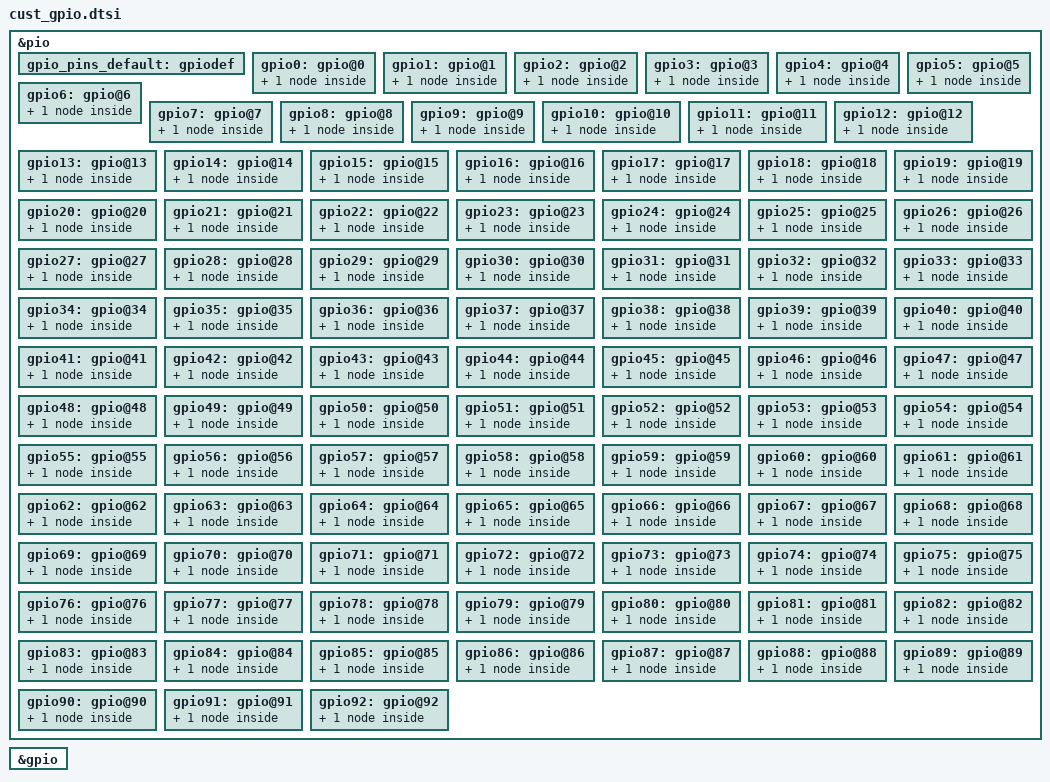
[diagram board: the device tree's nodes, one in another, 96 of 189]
/*
 * Generated by MTK SP DrvGen Version 03.13.6 for MT6580. Copyright MediaTek Inc. (C) 2013.
 * Sat Sep 10 16:33:29 2016
 * Do Not Modify the File.
 */

/*************************
 * GPIO DTSI File
*************************/

&pio {

	gpio_pins_default: gpiodef{
	};

	gpio0: gpio@0 {
		pins_cmd_dat {
			pins = <PINMUX_GPIO0__FUNC_SPI1_CS>;
			slew-rate = <0>;
			
			bias-pull-down = <00>;
			output-low;
			input-schmitt-enable = <0>;
		};
	};

	gpio1: gpio@1 {
		pins_cmd_dat {
			pins = <PINMUX_GPIO1__FUNC_SPI1_SCK>;
			slew-rate = <1>;
			
			bias-pull-down = <00>;
			output-low;
			input-schmitt-enable = <0>;
		};
	};

	gpio2: gpio@2 {
		pins_cmd_dat {
			pins = <PINMUX_GPIO2__FUNC_SPI1_MOSI>;
			slew-rate = <1>;
			bias-disable;
			bias-pull-down = <00>;
			output-low;
			input-schmitt-enable = <0>;
		};
	};

	gpio3: gpio@3 {
		pins_cmd_dat {
			pins = <PINMUX_GPIO3__FUNC_SPI1_MISO>;
			slew-rate = <0>;
			
			bias-pull-down = <11>;
			output-low;
			input-schmitt-enable = <0>;
		};
	};

	gpio4: gpio@4 {
		pins_cmd_dat {
			pins = <PINMUX_GPIO4__FUNC_GPIO4>;
			slew-rate = <1>;
			bias-disable;
			bias-pull-down = <00>;
			output-high;
			input-schmitt-enable = <0>;
		};
	};

	gpio5: gpio@5 {
		pins_cmd_dat {
			pins = <PINMUX_GPIO5__FUNC_EINT5>;
			slew-rate = <0>;
			
			bias-pull-down = <00>;
			output-low;
			input-schmitt-enable = <1>;
		};
	};

	gpio6: gpio@6 {
		pins_cmd_dat {
			pins = <PINMUX_GPIO6__FUNC_EINT6>;
			slew-rate = <0>;
			
			bias-pull-down = <11>;
			output-high;
			input-schmitt-enable = <0>;
		};
	};

	gpio7: gpio@7 {
		pins_cmd_dat {
			pins = <PINMUX_GPIO7__FUNC_GPIO7>;
			slew-rate = <1>;
			bias-disable;
			bias-pull-down = <00>;
			output-low;
			input-schmitt-enable = <0>;
		};
	};

	gpio8: gpio@8 {
		pins_cmd_dat {
			pins = <PINMUX_GPIO8__FUNC_GPIO8>;
			slew-rate = <1>;
			bias-disable;
			bias-pull-down = <00>;
			output-low;
			input-schmitt-enable = <0>;
		};
	};

	gpio9: gpio@9 {
		pins_cmd_dat {
			pins = <PINMUX_GPIO9__FUNC_GPIO9>;
			slew-rate = <0>;
			
			bias-pull-down = <00>;
			output-low;
			input-schmitt-enable = <0>;
		};
	};

	gpio10: gpio@10 {
		pins_cmd_dat {
			pins = <PINMUX_GPIO10__FUNC_GPIO10>;
			slew-rate = <0>;
			
			bias-pull-down = <00>;
			output-low;
			input-schmitt-enable = <0>;
		};
	};

	gpio11: gpio@11 {
		pins_cmd_dat {
			pins = <PINMUX_GPIO11__FUNC_EINT11>;
			slew-rate = <1>;
			bias-disable;
			bias-pull-down = <00>;
			output-low;
			input-schmitt-enable = <0>;
		};
	};

	gpio12: gpio@12 {
		pins_cmd_dat {
			pins = <PINMUX_GPIO12__FUNC_GPIO12>;
			slew-rate = <1>;
			bias-disable;
			bias-pull-down = <00>;
			output-low;
			input-schmitt-enable = <0>;
		};
	};

	gpio13: gpio@13 {
		pins_cmd_dat {
			pins = <PINMUX_GPIO13__FUNC_PMIC_EINT>;
			slew-rate = <0>;
			bias-disable;
			bias-pull-down = <00>;
			output-low;
			input-schmitt-enable = <0>;
		};
	};

	gpio14: gpio@14 {
		pins_cmd_dat {
			pins = <PINMUX_GPIO14__FUNC_EINT14>;
			slew-rate = <1>;
			
			bias-pull-down = <11>;
			output-low;
			input-schmitt-enable = <0>;
		};
	};

	gpio15: gpio@15 {
		pins_cmd_dat {
			pins = <PINMUX_GPIO15__FUNC_GPIO15>;
			slew-rate = <1>;
			
			bias-pull-down = <11>;
			output-low;
			input-schmitt-enable = <0>;
		};
	};

	gpio16: gpio@16 {
		pins_cmd_dat {
			pins = <PINMUX_GPIO16__FUNC_EINT0>;
			slew-rate = <1>;
			bias-disable;
			bias-pull-down = <00>;
			output-low;
			input-schmitt-enable = <0>;
		};
	};

	gpio17: gpio@17 {
		pins_cmd_dat {
			pins = <PINMUX_GPIO17__FUNC_GPIO17>;
			slew-rate = <1>;
			bias-disable;
			bias-pull-down = <00>;
			output-low;
			input-schmitt-enable = <0>;
		};
	};

	gpio18: gpio@18 {
		pins_cmd_dat {
			pins = <PINMUX_GPIO18__FUNC_GPIO18>;
			slew-rate = <1>;
			bias-disable;
			bias-pull-down = <00>;
			output-low;
			input-schmitt-enable = <0>;
		};
	};

	gpio19: gpio@19 {
		pins_cmd_dat {
			pins = <PINMUX_GPIO19__FUNC_GPIO19>;
			slew-rate = <0>;
			
			bias-pull-down = <00>;
			output-low;
			input-schmitt-enable = <0>;
		};
	};

	gpio20: gpio@20 {
		pins_cmd_dat {
			pins = <PINMUX_GPIO20__FUNC_GPIO20>;
			slew-rate = <1>;
			bias-disable;
			bias-pull-down = <00>;
			output-low;
			input-schmitt-enable = <0>;
		};
	};

	gpio21: gpio@21 {
		pins_cmd_dat {
			pins = <PINMUX_GPIO21__FUNC_GPIO21>;
			slew-rate = <1>;
			
			bias-pull-down = <11>;
			output-low;
			input-schmitt-enable = <0>;
		};
	};

	gpio22: gpio@22 {
		pins_cmd_dat {
			pins = <PINMUX_GPIO22__FUNC_SIM1_SCLK>;
			slew-rate = <1>;
			bias-disable;
			bias-pull-down = <00>;
			output-low;
			input-schmitt-enable = <0>;
		};
	};

	gpio23: gpio@23 {
		pins_cmd_dat {
			pins = <PINMUX_GPIO23__FUNC_SIM1_SIO>;
			slew-rate = <1>;
			bias-disable;
			bias-pull-down = <00>;
			output-low;
			input-schmitt-enable = <0>;
		};
	};

	gpio24: gpio@24 {
		pins_cmd_dat {
			pins = <PINMUX_GPIO24__FUNC_SIM2_SIO>;
			slew-rate = <1>;
			bias-disable;
			bias-pull-down = <00>;
			output-low;
			input-schmitt-enable = <0>;
		};
	};

	gpio25: gpio@25 {
		pins_cmd_dat {
			pins = <PINMUX_GPIO25__FUNC_SIM2_SCLK>;
			slew-rate = <1>;
			bias-disable;
			bias-pull-down = <00>;
			output-low;
			input-schmitt-enable = <0>;
		};
	};

	gpio26: gpio@26 {
		pins_cmd_dat {
			pins = <PINMUX_GPIO26__FUNC_AUD_CLK_MOSI>;
			slew-rate = <1>;
			bias-disable;
			bias-pull-down = <00>;
			output-low;
			input-schmitt-enable = <0>;
		};
	};

	gpio27: gpio@27 {
		pins_cmd_dat {
			pins = <PINMUX_GPIO27__FUNC_AUD_DAT_MOSI>;
			slew-rate = <1>;
			bias-disable;
			bias-pull-down = <00>;
			output-low;
			input-schmitt-enable = <0>;
		};
	};

	gpio28: gpio@28 {
		pins_cmd_dat {
			pins = <PINMUX_GPIO28__FUNC_AUD_DAT_MISO>;
			slew-rate = <0>;
			bias-disable;
			bias-pull-down = <00>;
			output-low;
			input-schmitt-enable = <0>;
		};
	};

	gpio29: gpio@29 {
		pins_cmd_dat {
			pins = <PINMUX_GPIO29__FUNC_PMIC_SPI_CSN>;
			slew-rate = <1>;
			bias-disable;
			bias-pull-down = <00>;
			output-low;
			input-schmitt-enable = <1>;
		};
	};

	gpio30: gpio@30 {
		pins_cmd_dat {
			pins = <PINMUX_GPIO30__FUNC_PMIC_SPI_SCK>;
			slew-rate = <1>;
			bias-disable;
			bias-pull-down = <00>;
			output-low;
			input-schmitt-enable = <1>;
		};
	};

	gpio31: gpio@31 {
		pins_cmd_dat {
			pins = <PINMUX_GPIO31__FUNC_PMIC_SPI_MOSI>;
			slew-rate = <1>;
			bias-disable;
			bias-pull-down = <00>;
			output-low;
			input-schmitt-enable = <1>;
		};
	};

	gpio32: gpio@32 {
		pins_cmd_dat {
			pins = <PINMUX_GPIO32__FUNC_PMIC_SPI_MISO>;
			slew-rate = <0>;
			bias-disable;
			bias-pull-down = <00>;
			output-low;
			input-schmitt-enable = <1>;
		};
	};

	gpio33: gpio@33 {
		pins_cmd_dat {
			pins = <PINMUX_GPIO33__FUNC_WATCHDOG>;
			slew-rate = <1>;
			bias-disable;
			bias-pull-down = <00>;
			output-low;
			input-schmitt-enable = <0>;
		};
	};

	gpio34: gpio@34 {
		pins_cmd_dat {
			pins = <PINMUX_GPIO34__FUNC_GPIO34>;
			slew-rate = <1>;
			bias-disable;
			bias-pull-down = <00>;
			output-low;
			input-schmitt-enable = <0>;
		};
	};

	gpio35: gpio@35 {
		pins_cmd_dat {
			pins = <PINMUX_GPIO35__FUNC_PAD_RDP0_A>;
			slew-rate = <0>;
			
			bias-pull-down = <00>;
			output-low;
			input-schmitt-enable = <0>;
		};
	};

	gpio36: gpio@36 {
		pins_cmd_dat {
			pins = <PINMUX_GPIO36__FUNC_PAD_RDN0_A>;
			slew-rate = <0>;
			
			bias-pull-down = <00>;
			output-low;
			input-schmitt-enable = <0>;
		};
	};

	gpio37: gpio@37 {
		pins_cmd_dat {
			pins = <PINMUX_GPIO37__FUNC_PAD_RDP1_A>;
			slew-rate = <0>;
			
			bias-pull-down = <00>;
			output-low;
			input-schmitt-enable = <0>;
		};
	};

	gpio38: gpio@38 {
		pins_cmd_dat {
			pins = <PINMUX_GPIO38__FUNC_PAD_RDN1_A>;
			slew-rate = <0>;
			
			bias-pull-down = <00>;
			output-low;
			input-schmitt-enable = <0>;
		};
	};

	gpio39: gpio@39 {
		pins_cmd_dat {
			pins = <PINMUX_GPIO39__FUNC_PAD_RCP_A>;
			slew-rate = <0>;
			
			bias-pull-down = <00>;
			output-low;
			input-schmitt-enable = <0>;
		};
	};

	gpio40: gpio@40 {
		pins_cmd_dat {
			pins = <PINMUX_GPIO40__FUNC_PAD_RCN_A>;
			slew-rate = <0>;
			
			bias-pull-down = <00>;
			output-low;
			input-schmitt-enable = <0>;
		};
	};

	gpio41: gpio@41 {
		pins_cmd_dat {
			pins = <PINMUX_GPIO41__FUNC_MC0_CK>;
			slew-rate = <1>;
			bias-disable;
			bias-pull-down = <00>;
			output-low;
			input-schmitt-enable = <0>;
		};
	};

	gpio42: gpio@42 {
		pins_cmd_dat {
			pins = <PINMUX_GPIO42__FUNC_MC0_CMD>;
			slew-rate = <0>;
			
			bias-pull-down = <11>;
			output-low;
			input-schmitt-enable = <0>;
		};
	};

	gpio43: gpio@43 {
		pins_cmd_dat {
			pins = <PINMUX_GPIO43__FUNC_MC0_DAT0>;
			slew-rate = <0>;
			
			bias-pull-down = <11>;
			output-low;
			input-schmitt-enable = <0>;
		};
	};

	gpio44: gpio@44 {
		pins_cmd_dat {
			pins = <PINMUX_GPIO44__FUNC_MC0_DAT1>;
			slew-rate = <0>;
			
			bias-pull-down = <11>;
			output-low;
			input-schmitt-enable = <0>;
		};
	};

	gpio45: gpio@45 {
		pins_cmd_dat {
			pins = <PINMUX_GPIO45__FUNC_MC0_DAT2>;
			slew-rate = <0>;
			
			bias-pull-down = <11>;
			output-low;
			input-schmitt-enable = <0>;
		};
	};

	gpio46: gpio@46 {
		pins_cmd_dat {
			pins = <PINMUX_GPIO46__FUNC_MC0_DAT3>;
			slew-rate = <0>;
			
			bias-pull-down = <11>;
			output-low;
			input-schmitt-enable = <0>;
		};
	};

	gpio47: gpio@47 {
		pins_cmd_dat {
			pins = <PINMUX_GPIO47__FUNC_MC0_DAT4>;
			slew-rate = <0>;
			
			bias-pull-down = <11>;
			output-low;
			input-schmitt-enable = <0>;
		};
	};

	gpio48: gpio@48 {
		pins_cmd_dat {
			pins = <PINMUX_GPIO48__FUNC_MC0_DAT5>;
			slew-rate = <0>;
			
			bias-pull-down = <11>;
			output-low;
			input-schmitt-enable = <0>;
		};
	};

	gpio49: gpio@49 {
		pins_cmd_dat {
			pins = <PINMUX_GPIO49__FUNC_MC0_DAT6>;
			slew-rate = <0>;
			
			bias-pull-down = <11>;
			output-low;
			input-schmitt-enable = <0>;
		};
	};

	gpio50: gpio@50 {
		pins_cmd_dat {
			pins = <PINMUX_GPIO50__FUNC_MC0_DAT7>;
			slew-rate = <0>;
			
			bias-pull-down = <11>;
			output-low;
			input-schmitt-enable = <0>;
		};
	};

	gpio51: gpio@51 {
		pins_cmd_dat {
			pins = <PINMUX_GPIO51__FUNC_MC0_RSTB>;
			slew-rate = <1>;
			bias-disable;
			bias-pull-down = <00>;
			output-high;
			input-schmitt-enable = <0>;
		};
	};

	gpio52: gpio@52 {
		pins_cmd_dat {
			pins = <PINMUX_GPIO52__FUNC_MSDC1_CLK>;
			slew-rate = <1>;
			bias-disable;
			bias-pull-down = <00>;
			output-low;
			input-schmitt-enable = <0>;
		};
	};

	gpio53: gpio@53 {
		pins_cmd_dat {
			pins = <PINMUX_GPIO53__FUNC_MSDC1_CMD>;
			slew-rate = <0>;
			
			bias-pull-down = <11>;
			output-low;
			input-schmitt-enable = <0>;
		};
	};

	gpio54: gpio@54 {
		pins_cmd_dat {
			pins = <PINMUX_GPIO54__FUNC_MSDC1_DAT3>;
			slew-rate = <0>;
			
			bias-pull-down = <11>;
			output-low;
			input-schmitt-enable = <0>;
		};
	};

	gpio55: gpio@55 {
		pins_cmd_dat {
			pins = <PINMUX_GPIO55__FUNC_MSDC1_DAT2>;
			slew-rate = <0>;
			
			bias-pull-down = <11>;
			output-low;
			input-schmitt-enable = <0>;
		};
	};

	gpio56: gpio@56 {
		pins_cmd_dat {
			pins = <PINMUX_GPIO56__FUNC_MSDC1_DAT1>;
			slew-rate = <0>;
			
			bias-pull-down = <11>;
			output-low;
			input-schmitt-enable = <0>;
		};
	};

	gpio57: gpio@57 {
		pins_cmd_dat {
			pins = <PINMUX_GPIO57__FUNC_MSDC1_DAT0>;
			slew-rate = <0>;
			
			bias-pull-down = <11>;
			output-low;
			input-schmitt-enable = <0>;
		};
	};

	gpio58: gpio@58 {
		pins_cmd_dat {
			pins = <PINMUX_GPIO58__FUNC_I2C_SCL0>;
			slew-rate = <0>;
			bias-disable;
			bias-pull-down = <00>;
			output-low;
			input-schmitt-enable = <0>;
		};
	};

	gpio59: gpio@59 {
		pins_cmd_dat {
			pins = <PINMUX_GPIO59__FUNC_I2C_SCL1>;
			slew-rate = <0>;
			bias-disable;
			bias-pull-down = <00>;
			output-low;
			input-schmitt-enable = <0>;
		};
	};

	gpio60: gpio@60 {
		pins_cmd_dat {
			pins = <PINMUX_GPIO60__FUNC_I2C_SCL2>;
			slew-rate = <0>;
			bias-disable;
			bias-pull-down = <00>;
			output-low;
			input-schmitt-enable = <0>;
		};
	};

	gpio61: gpio@61 {
		pins_cmd_dat {
			pins = <PINMUX_GPIO61__FUNC_I2C_SDA0>;
			slew-rate = <0>;
			bias-disable;
			bias-pull-down = <00>;
			output-low;
			input-schmitt-enable = <0>;
		};
	};

	gpio62: gpio@62 {
		pins_cmd_dat {
			pins = <PINMUX_GPIO62__FUNC_I2C_SDA1>;
			slew-rate = <0>;
			bias-disable;
			bias-pull-down = <00>;
			output-low;
			input-schmitt-enable = <0>;
		};
	};

	gpio63: gpio@63 {
		pins_cmd_dat {
			pins = <PINMUX_GPIO63__FUNC_I2C_SDA2>;
			slew-rate = <0>;
			bias-disable;
			bias-pull-down = <00>;
			output-low;
			input-schmitt-enable = <0>;
		};
	};

	gpio64: gpio@64 {
		pins_cmd_dat {
			pins = <PINMUX_GPIO64__FUNC_KPCOL0>;
			slew-rate = <0>;
			
			bias-pull-down = <11>;
			output-low;
			input-schmitt-enable = <0>;
		};
	};

	gpio65: gpio@65 {
		pins_cmd_dat {
			pins = <PINMUX_GPIO65__FUNC_KPROW1>;
			slew-rate = <1>;
			bias-disable;
			bias-pull-down = <00>;
			output-low;
			input-schmitt-enable = <0>;
		};
	};

	gpio66: gpio@66 {
		pins_cmd_dat {
			pins = <PINMUX_GPIO66__FUNC_DISP_PWM>;
			slew-rate = <1>;
			bias-disable;
			bias-pull-down = <00>;
			output-low;
			input-schmitt-enable = <0>;
		};
	};

	gpio67: gpio@67 {
		pins_cmd_dat {
			pins = <PINMUX_GPIO67__FUNC_KPCOL1>;
			slew-rate = <0>;
			
			bias-pull-down = <11>;
			output-low;
			input-schmitt-enable = <0>;
		};
	};

	gpio68: gpio@68 {
		pins_cmd_dat {
			pins = <PINMUX_GPIO68__FUNC_DSI_TE>;
			slew-rate = <0>;
			bias-disable;
			bias-pull-down = <00>;
			output-low;
			input-schmitt-enable = <0>;
		};
	};

	gpio69: gpio@69 {
		pins_cmd_dat {
			pins = <PINMUX_GPIO69__FUNC_KPROW0>;
			slew-rate = <1>;
			bias-disable;
			bias-pull-down = <00>;
			output-low;
			input-schmitt-enable = <0>;
		};
	};

	gpio70: gpio@70 {
		pins_cmd_dat {
			pins = <PINMUX_GPIO70__FUNC_LCM_RST>;
			slew-rate = <1>;
			bias-disable;
			bias-pull-down = <00>;
			output-low;
			input-schmitt-enable = <0>;
		};
	};

	gpio71: gpio@71 {
		pins_cmd_dat {
			pins = <PINMUX_GPIO71__FUNC_GPIO71>;
			slew-rate = <1>;
			bias-disable;
			bias-pull-down = <00>;
			output-low;
			input-schmitt-enable = <0>;
		};
	};

	gpio72: gpio@72 {
		pins_cmd_dat {
			pins = <PINMUX_GPIO72__FUNC_CAM_CLK0>;
			slew-rate = <1>;
			bias-disable;
			bias-pull-down = <00>;
			output-low;
			input-schmitt-enable = <0>;
		};
	};

	gpio73: gpio@73 {
		pins_cmd_dat {
			pins = <PINMUX_GPIO73__FUNC_GPIO73>;
			slew-rate = <1>;
			bias-disable;
			bias-pull-down = <00>;
			output-low;
			input-schmitt-enable = <0>;
		};
	};

	gpio74: gpio@74 {
		pins_cmd_dat {
			pins = <PINMUX_GPIO74__FUNC_GPIO74>;
			slew-rate = <1>;
			bias-disable;
			bias-pull-down = <00>;
			output-low;
			input-schmitt-enable = <0>;
		};
	};

	gpio75: gpio@75 {
		pins_cmd_dat {
			pins = <PINMUX_GPIO75__FUNC_CAM_CLK1>;
			slew-rate = <1>;
			bias-disable;
			bias-pull-down = <00>;
			output-low;
			input-schmitt-enable = <0>;
		};
	};

	gpio76: gpio@76 {
		pins_cmd_dat {
			pins = <PINMUX_GPIO76__FUNC_GPIO76>;
			slew-rate = <1>;
			bias-disable;
			bias-pull-down = <00>;
			output-low;
			input-schmitt-enable = <0>;
		};
	};

	gpio77: gpio@77 {
		pins_cmd_dat {
			pins = <PINMUX_GPIO77__FUNC_MD_EINT1>;
			slew-rate = <0>;
			
			bias-pull-down = <11>;
			output-high;
			input-schmitt-enable = <0>;
		};
	};

	gpio78: gpio@78 {
		pins_cmd_dat {
			pins = <PINMUX_GPIO78__FUNC_MD_EINT2>;
			slew-rate = <0>;
			
			bias-pull-down = <11>;
			output-high;
			input-schmitt-enable = <0>;
		};
	};

	gpio79: gpio@79 {
		pins_cmd_dat {
			pins = <PINMUX_GPIO79__FUNC_VM1>;
			slew-rate = <0>;
			bias-disable;
			bias-pull-down = <00>;
			output-low;
			input-schmitt-enable = <0>;
		};
	};

	gpio80: gpio@80 {
		pins_cmd_dat {
			pins = <PINMUX_GPIO80__FUNC_VM0>;
			slew-rate = <0>;
			bias-disable;
			bias-pull-down = <00>;
			output-low;
			input-schmitt-enable = <0>;
		};
	};

	gpio81: gpio@81 {
		pins_cmd_dat {
			pins = <PINMUX_GPIO81__FUNC_BPI_BUS11>;
			slew-rate = <1>;
			bias-disable;
			bias-pull-down = <11>;
			output-low;
			input-schmitt-enable = <0>;
		};
	};

	gpio82: gpio@82 {
		pins_cmd_dat {
			pins = <PINMUX_GPIO82__FUNC_BPI_BUS10>;
			slew-rate = <1>;
			bias-disable;
			bias-pull-down = <00>;
			output-low;
			input-schmitt-enable = <0>;
		};
	};

	gpio83: gpio@83 {
		pins_cmd_dat {
			pins = <PINMUX_GPIO83__FUNC_EINT2>;
			slew-rate = <0>;
			
			bias-pull-down = <00>;
			output-low;
			input-schmitt-enable = <0>;
		};
	};

	gpio84: gpio@84 {
		pins_cmd_dat {
			pins = <PINMUX_GPIO84__FUNC_GPIO84>;
			slew-rate = <0>;
			
			bias-pull-down = <00>;
			output-low;
			input-schmitt-enable = <0>;
		};
	};

	gpio85: gpio@85 {
		pins_cmd_dat {
			pins = <PINMUX_GPIO85__FUNC_BPI_BUS7>;
			slew-rate = <1>;
			bias-disable;
			bias-pull-down = <00>;
			output-low;
			input-schmitt-enable = <0>;
		};
	};

	gpio86: gpio@86 {
		pins_cmd_dat {
			pins = <PINMUX_GPIO86__FUNC_BPI_BUS6>;
			slew-rate = <1>;
			bias-disable;
			bias-pull-down = <00>;
			output-low;
			input-schmitt-enable = <0>;
		};
	};

	gpio87: gpio@87 {
		pins_cmd_dat {
			pins = <PINMUX_GPIO87__FUNC_BPI_BUS5>;
			slew-rate = <1>;
			bias-disable;
			bias-pull-down = <00>;
			output-low;
			input-schmitt-enable = <0>;
		};
	};

	gpio88: gpio@88 {
		pins_cmd_dat {
			pins = <PINMUX_GPIO88__FUNC_BPI_BUS4>;
			slew-rate = <1>;
			bias-disable;
			bias-pull-down = <00>;
			output-low;
			input-schmitt-enable = <0>;
		};
	};

	gpio89: gpio@89 {
		pins_cmd_dat {
			pins = <PINMUX_GPIO89__FUNC_BPI_BUS3>;
			slew-rate = <1>;
			bias-disable;
			bias-pull-down = <00>;
			output-low;
			input-schmitt-enable = <0>;
		};
	};

	gpio90: gpio@90 {
		pins_cmd_dat {
			pins = <PINMUX_GPIO90__FUNC_BPI_BUS2>;
			slew-rate = <1>;
			bias-disable;
			bias-pull-down = <00>;
			output-low;
			input-schmitt-enable = <0>;
		};
	};

	gpio91: gpio@91 {
		pins_cmd_dat {
			pins = <PINMUX_GPIO91__FUNC_BPI_BUS1>;
			slew-rate = <1>;
			bias-disable;
			bias-pull-down = <00>;
			output-low;
			input-schmitt-enable = <0>;
		};
	};

	gpio92: gpio@92 {
		pins_cmd_dat {
			pins = <PINMUX_GPIO92__FUNC_BPI_BUS0>;
			slew-rate = <1>;
			bias-disable;
			bias-pull-down = <00>;
			output-low;
			input-schmitt-enable = <0>;
		};
	};

};

&gpio {
	pinctrl-names = "default","gpio0","gpio1","gpio2","gpio3","gpio4","gpio5","gpio6","gpio7","gpio8",
"gpio9","gpio10","gpio11","gpio12","gpio13","gpio14","gpio15","gpio16","gpio17","gpio18","gpio19","gpio20",
"gpio21","gpio22","gpio23","gpio24","gpio25","gpio26","gpio27","gpio28","gpio29","gpio30","gpio31","gpio32",
"gpio33","gpio34","gpio35","gpio36","gpio37","gpio38","gpio39","gpio40","gpio41","gpio42","gpio43","gpio44",
"gpio45","gpio46","gpio47","gpio48","gpio49","gpio50","gpio51","gpio52","gpio53","gpio54","gpio55","gpio56",
"gpio57","gpio58","gpio59","gpio60","gpio61","gpio62","gpio63","gpio64","gpio65","gpio66","gpio67","gpio68",
"gpio69","gpio70","gpio71","gpio72","gpio73","gpio74","gpio75","gpio76","gpio77","gpio78","gpio79","gpio80",
"gpio81","gpio82","gpio83","gpio84","gpio85","gpio86","gpio87","gpio88","gpio89","gpio90","gpio91","gpio92";
	pinctrl-0 = <&gpio_pins_default>;
	pinctrl-1 = <&gpio0>;
	pinctrl-2 = <&gpio1>;
	pinctrl-3 = <&gpio2>;
	pinctrl-4 = <&gpio3>;
	pinctrl-5 = <&gpio4>;
	pinctrl-6 = <&gpio5>;
	pinctrl-7 = <&gpio6>;
	pinctrl-8 = <&gpio7>;
	pinctrl-9 = <&gpio8>;
	pinctrl-10 = <&gpio9>;
	pinctrl-11 = <&gpio10>;
	pinctrl-12 = <&gpio11>;
	pinctrl-13 = <&gpio12>;
	pinctrl-14 = <&gpio13>;
	pinctrl-15 = <&gpio14>;
	pinctrl-16 = <&gpio15>;
	pinctrl-17 = <&gpio16>;
	pinctrl-18 = <&gpio17>;
	pinctrl-19 = <&gpio18>;
	pinctrl-20 = <&gpio19>;
	pinctrl-21 = <&gpio20>;
	pinctrl-22 = <&gpio21>;
	pinctrl-23 = <&gpio22>;
	pinctrl-24 = <&gpio23>;
	pinctrl-25 = <&gpio24>;
	pinctrl-26 = <&gpio25>;
	pinctrl-27 = <&gpio26>;
	pinctrl-28 = <&gpio27>;
	pinctrl-29 = <&gpio28>;
	pinctrl-30 = <&gpio29>;
	pinctrl-31 = <&gpio30>;
	pinctrl-32 = <&gpio31>;
	pinctrl-33 = <&gpio32>;
	pinctrl-34 = <&gpio33>;
	pinctrl-35 = <&gpio34>;
	pinctrl-36 = <&gpio35>;
	pinctrl-37 = <&gpio36>;
	pinctrl-38 = <&gpio37>;
	pinctrl-39 = <&gpio38>;
	pinctrl-40 = <&gpio39>;
	pinctrl-41 = <&gpio40>;
	pinctrl-42 = <&gpio41>;
	pinctrl-43 = <&gpio42>;
	pinctrl-44 = <&gpio43>;
	pinctrl-45 = <&gpio44>;
	pinctrl-46 = <&gpio45>;
	pinctrl-47 = <&gpio46>;
	pinctrl-48 = <&gpio47>;
	pinctrl-49 = <&gpio48>;
	pinctrl-50 = <&gpio49>;
	pinctrl-51 = <&gpio50>;
	pinctrl-52 = <&gpio51>;
	pinctrl-53 = <&gpio52>;
	pinctrl-54 = <&gpio53>;
	pinctrl-55 = <&gpio54>;
	pinctrl-56 = <&gpio55>;
	pinctrl-57 = <&gpio56>;
	pinctrl-58 = <&gpio57>;
	pinctrl-59 = <&gpio58>;
	pinctrl-60 = <&gpio59>;
	pinctrl-61 = <&gpio60>;
	pinctrl-62 = <&gpio61>;
	pinctrl-63 = <&gpio62>;
	pinctrl-64 = <&gpio63>;
	pinctrl-65 = <&gpio64>;
	pinctrl-66 = <&gpio65>;
	pinctrl-67 = <&gpio66>;
	pinctrl-68 = <&gpio67>;
	pinctrl-69 = <&gpio68>;
	pinctrl-70 = <&gpio69>;
	pinctrl-71 = <&gpio70>;
	pinctrl-72 = <&gpio71>;
	pinctrl-73 = <&gpio72>;
	pinctrl-74 = <&gpio73>;
	pinctrl-75 = <&gpio74>;
	pinctrl-76 = <&gpio75>;
	pinctrl-77 = <&gpio76>;
	pinctrl-78 = <&gpio77>;
	pinctrl-79 = <&gpio78>;
	pinctrl-80 = <&gpio79>;
	pinctrl-81 = <&gpio80>;
	pinctrl-82 = <&gpio81>;
	pinctrl-83 = <&gpio82>;
	pinctrl-84 = <&gpio83>;
	pinctrl-85 = <&gpio84>;
	pinctrl-86 = <&gpio85>;
	pinctrl-87 = <&gpio86>;
	pinctrl-88 = <&gpio87>;
	pinctrl-89 = <&gpio88>;
	pinctrl-90 = <&gpio89>;
	pinctrl-91 = <&gpio90>;
	pinctrl-92 = <&gpio91>;

	status = "okay";

};
